# STM32WBA64 register map
File version: 1.1
CPU: CM33 r0p1, little endian, MPU, FPU, 4 interrupt priority bits
Registers are 32-bit, read-write, reset 0x0 unless marked. A register's access mark holds for its fields unless they carry their own. Offsets are from the block's base; [hi:lo] are bit positions.

## SYSCFG — SYSCFG address block description
Base 0x46000400
Same registers: SEC_SYSCFG 0x56000400
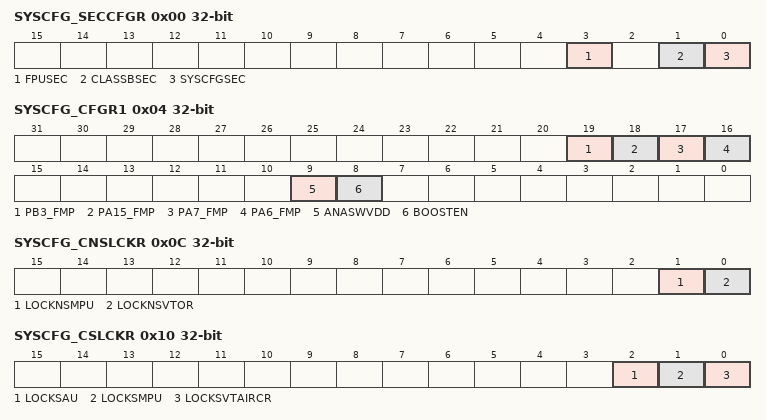
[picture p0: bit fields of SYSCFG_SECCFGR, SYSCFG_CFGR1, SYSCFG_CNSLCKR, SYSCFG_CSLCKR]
0x00 SYSCFG_SECCFGR — SYSCFG secure configuration register
  [3] FPUSEC — FPU security
    0=SYSCFG_FPUIMR register can be read and written by secure and nonsecure access; 1=SYSCFG_FPUIMR register can be read and written by secure access only
  [1] CLASSBSEC — Class B security
    0=SYSCFG_CFGR2 register can be read and written by secure and nonsecure access; 1=SYSCFG_CFGR2 register can be read and written by secure access only
  [0] SYSCFGSEC — SYSCFG clock control, memory erase status and compensation cell registers security
    0=SYSCFG configuration clock in RCC registers, SYSCFG_MESR and SYSCFG_CCCSR, SYSCFG_CCVR and SYSCFG_CCCR can be read and written by secure and nonsecure access; 1=SYSCFG configuration clock in RCC registers, SYSCFG_MESR and SYSCFG_CCCSR, SYSCFG_CCVR and SYSCFG_CCCR can be read and written by secure access only
0x04 SYSCFG_CFGR1 — SYSCFG configuration register 1
  [19] PB3_FMP — Fast-mode Plus drive capability activation on PB3
    0=PB3 pin operates in standard mode when not used by I2C peripheral; 1=Fast-mode Plus mode is enabled on PAB3 pin and the GPIO speed control is bypassed
  [18] PA15_FMP — Fast-mode Plus drive capability activation on PA15
    0=PA15 pin operates in standard mode when not used by I2C peripheral; 1=Fast-mode Plus mode is enabled on PA15 pin and the GPIO speed control is bypassed
  [17] PA7_FMP — Fast-mode Plus drive capability activation on PA7
    0=PA7 pin operates in standard mode when not used by I2C peripheral; 1=Fast-mode Plus mode is enabled on PA7 pin and the GPIO speed control is bypassed
  [16] PA6_FMP — Fast-mode Plus drive capability activation on PA6
    0=PA6 pin operates in standard mode when not used by I2C peripheral; 1=Fast-mode Plus mode is enabled on PA6 pin and the GPIO speed control is bypassed
  [9] ANASWVDD — GPIO analog switch control voltage selection
    0=I/O analog switches are supplied by Vless thansub DDAless than/sub or booster when booster is ON; 1=I/O analog switches are supplied by Vless thansub DDless than/sub 
  [8] BOOSTEN — I/O analog switch voltage booster enable
    0=I/O analog switches are supplied by Vless thansub DDAless than/sub voltage; 1=I/O analog switches are supplied by a dedicated voltage booster (supplied by Vless thansub DDless than/sub )
0x08 SYSCFG_FPUIMR reset 0x1F — SYSCFG FPU interrupt mask register
  [5:0] FPU_IE — Floating point unit interrupts enable bits
0x0C SYSCFG_CNSLCKR — SYSCFG CPU nonsecure lock register
  [1] LOCKNSMPU — Nonsecure MPU registers lock
    0=nonsecure MPU registers write enabled; 1=nonsecure MPU registers write disabled
  [0] LOCKNSVTOR — VTOR_NS register lock
    0=VTOR_NS register write enabled; 1=VTOR_NS register write disabled
0x10 SYSCFG_CSLCKR — SYSCFG CPU secure lock register
  [2] LOCKSAU — SAU registers lock
    0=SAU registers write enabled; 1=SAU registers write disabled
  [1] LOCKSMPU — Secure MPU registers lock
    0=Secure MPU registers writes enabled; 1=Secure MPU registers writes disabled
  [0] LOCKSVTAIRCR — VTOR_S register and AIRCR register bits lock
    0=VTOR_S register PRIS and BFHFNMINS bits in the AIRCR register write enabled; 1=VTOR_S register PRIS and BFHFNMINS bits in the AIRCR register write disabled
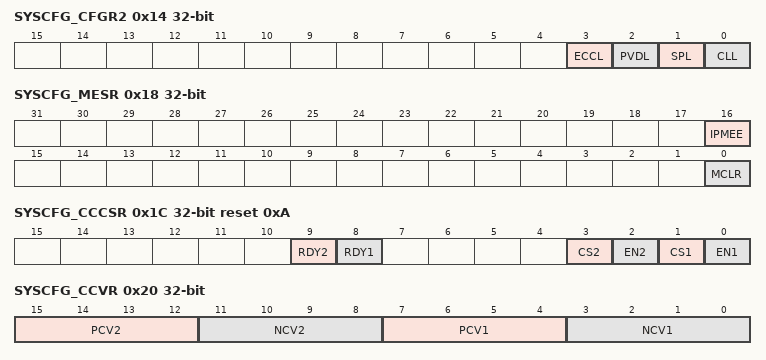
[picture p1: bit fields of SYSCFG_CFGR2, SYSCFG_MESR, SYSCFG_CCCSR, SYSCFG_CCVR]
0x14 SYSCFG_CFGR2 — SYSCFG configuration register 2
  [3] ECCL — ECC lock
    0=ECC double error disconnected from TIM1/16/17 break input; 1=ECC double error connected to TIM1/16/17 break input
  [2] PVDL — PVD lock enable bit
    0=PVD interrupt disconnected from TIM1/16/17 break input; 1=PVD interrupt connected to TIM1/16/17 break input
  [1] SPL — SRAM2 parity lock bit
    0=SRAM2 parity error disconnected from TIM1/16/17 break inputs; 1=SRAM2 parity error connected to TIM1/16/17 break inputs
  [0] CLL — Cortex-M33 LOCKUP (hardfault) output enable
    0=Cortex-M33 LOCKUP output disconnected from TIM1/16/17 break inputs; 1=Cortex-M33 LOCKUP output connected to TIM1/16/17 break inputs
0x18 SYSCFG_MESR — SYSCFG memory erase status register
  [16] IPMEE — ICACHE and PKA SRAM erase status
    0=ICACHE and PKA SRAM erase ongoing if not yet cleared by software; 1=ICACHE and PKA SRAM erase done
  [0] MCLR — Device memories erase status
    0=Memory erase ongoing if not yet cleared by software; 1=Memory erase done
0x1C SYSCFG_CCCSR reset 0xA — SYSCFG compensation cell control/status register
  [9] RDY2 ro — VDDIO2 I/Os compensation cell ready flag
    0=VDDIO2 I/Os compensation cell not ready; 1=VDDIO2 I/Os compensation cell ready
  [8] RDY1 ro — VDD I/Os compensation cell ready flag
    0=VDD I/Os compensation cell not ready; 1=VDD I/Os compensation cell ready
  [3] CS2 — VDDIO2 I/Os code selection
    0=VDDIO2 I/Os code from the cell (available in the SYSCFG_CCVR); 1=VDDIO2 I/Os code from the SYSCFG compensation cell code register (SYSCFG_CCCR)
  [2] EN2 — VDDIO2 I/Os compensation cell enable
    0=VDDIO2 I/Os compensation cell disabled; 1=VDDIO2 I/Os compensation cell enabled
  [1] CS1 — VDD I/Os code selection
    0=VDD I/Os code from the cell (available in the SYSCFG_CCVR); 1=VDD I/Os code from the SYSCFG compensation cell code register (SYSCFG_CCCR)
  [0] EN1 — VDD I/Os compensation cell enable
    0=VDD I/Os compensation cell disabled; 1=VDD I/Os compensation cell enabled
0x20 SYSCFG_CCVR ro — SYSCFG compensation cell value register
  [15:12] PCV2 — PMOS compensation value of the I/Os supplied by Vless thansub DDIO2less than/sub
  [11:8] NCV2 — NMOS compensation value of the I/Os supplied by Vless thansub DDIO2less than/sub
  [7:4] PCV1 — PMOS compensation value of the I/Os supplied by Vless thansub DDless than/sub
  [3:0] NCV1 — NMOS compensation value of the I/Os supplied by Vless thansub DDless than/sub
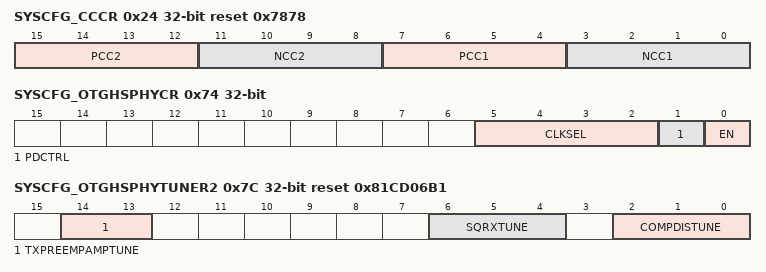
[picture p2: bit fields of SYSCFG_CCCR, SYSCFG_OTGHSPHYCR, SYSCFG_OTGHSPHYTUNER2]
0x24 SYSCFG_CCCR reset 0x7878 — SYSCFG compensation cell code register
  [15:12] PCC2 — PMOS compensation code of the I/Os supplied by Vless thansub DDIO2less than/sub
  [11:8] NCC2 — NMOS compensation code of the I/Os supplied by Vless thansub DDIO2less than/sub
  [7:4] PCC1 — PMOS compensation code of the I/Os supplied by Vless thansub DDless than/sub
  [3:0] NCC1 — NMOS compensation code of the I/Os supplied by Vless thansub DDless than/sub
0x2C SYSCFG_RSSCMDR — SYSCFG RSS command register
  [15:0] RSSCMD — RSS commands
0x74 SYSCFG_OTGHSPHYCR — SYSCFG USB OTG_HS PHY control register
  [5:2] CLKSEL — USB OTG_HS PHY kernel clock frequency selection
    0=No clock; 3=16 MHz; 8=19; 9=20 MHz; 10=24 MHz; 11=32 MHz; 14=26 MHz
  [1] PDCTRL — USB OTG_HS PHY common block power-down control
    0=In SUSPEND, USB OTG_HS PHY state machine, bias and PLL are powered; 1=In SUSPEND, USB OTG_HS PHY state machine, bias and PLL are powered down
  [0] EN — USB OTG_HS PHY enable
    0=USB OTG_HS PHY disabled and in reset; 1=USB OTG_HS PHY enabled
0x7C SYSCFG_OTGHSPHYTUNER2 reset 0x81CD06B1 — SYSCFG USB OTG_HS PHY tune register 2
  [14:13] TXPREEMPAMPTUNE — USB OTG_HS PHY transmitter pre-emphasis current control
    0=transmitter pre-emphasis current disabled; 1=transmitter 1x pre-emphasis current; 2=transmitter 2x pre-emphasis current; 3=transmitter 3x pre-emphasis current
  [6:4] SQRXTUNE — USB OTG_HS PHY squelch threshold adjustment
    0=+15% (recommended); 3=0% (default)
  [2:0] COMPDISTUNE — USB OTG_HS PHY disconnect threshold adjustment
    2=+5; 1=0% (default)
